# STM32H5F5xx register map
File version: 1.0
Registers are 32-bit, read-write, reset 0x0 unless marked. A register's access mark holds for its fields unless they carry their own. Offsets are from the block's base; [hi:lo] are bit positions; {n}, {i} and the like mark numbered series; 'fields as' and 'values as' point back to an identical list.

## RCC — Reset and Clock Control
Base 0x44020C00
Same registers: RCC_S 0x54020C00
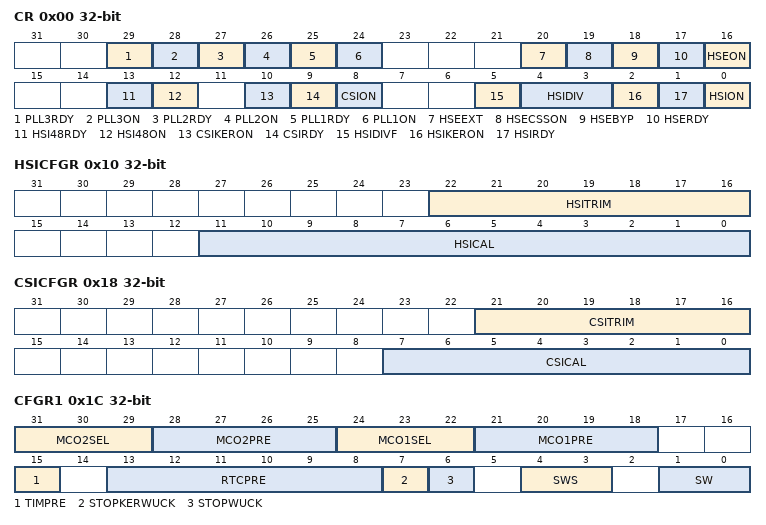
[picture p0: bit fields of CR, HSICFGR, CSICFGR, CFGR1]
0x00 CR — RCC clock control register
  [29] PLL3RDY — PLL3 ready
  [28] PLL3ON — PLL3 enable
  [27] PLL2RDY — PLL2 ready
  [26] PLL2ON — PLL2 enable
  [25] PLL1RDY — System PLL clock ready
  [24] PLL1ON — System PLL clock enable
  [20] HSEEXT — External High Speed clock type in Bypass mode
    0=ANALOG_TYPE (ANALOG clock used as HSE external clock source); 1=DIGITAL_TYPE (DIGITAL clock used as HSE external clock source)
  [19] HSECSSON — HSE Clock Security System enable
  [18] HSEBYP — External High Speed oscillator (HSE) clock bypass
  [17] HSERDY — External High Speed oscillator (HSE) clock ready
  [16] HSEON — External High Speed oscillator (HSE) clock enable
  [13] HSI48RDY — HSI48 clock ready
  [12] HSI48ON — HSI48 clock enable
  [10] CSIKERON — The Internal RC 4MHz oscillator (CSI) clock enable for some IPs Kernel
  [9] CSIRDY — The Internal RC 4MHz oscillator (CSI) clock ready
  [8] CSION — The Internal RC 4MHz oscillator (CSI) clock enable
  [5] HSIDIVF — HSI Divider flag
  [4:3] HSIDIV — Internal High Speed clock divider selection
    0=DIV_1 (HSI_DIV1 clock activation); 1=DIV_2 (HSI_DIV2 clock activation); 2=DIV_4 (HSI_DIV4 clock activation); 3=DIV_8 (HSI_DIV8 clock activation)
  [2] HSIKERON — Internal High Speed oscillator (HSI) clock enable for some IPs Kernel
  [1] HSIRDY — Internal High Speed oscillator (HSI) clock ready flag
  [0] HSION — Internal High Speed oscillator (HSI) clock enable
0x10 HSICFGR — RCC HSI Clock Calibration Register
  [22:16] HSITRIM — HSITRIM[6:0] bits
  [11:0] HSICAL — HSICAL[11:0] bits
0x14 CRRCR — RCC Clock Recovery RC Register
  [9:0] HSI48CAL — HSI48CAL[8:0] bits
0x18 CSICFGR — RCC CSI Clock Calibration Register
  [21:16] CSITRIM — CSITRIM[5:0] bits
  [7:0] CSICAL — CSICAL[7:0] bits
0x1C CFGR1 — RCC clock configuration register 1
  [31:29] MCO2SEL
  [28:25] MCO2PRE
  [24:22] MCO1SEL
  [21:18] MCO1PRE
  [15] TIMPRE
    0=TWICE; 1=FOUR_TIMES
  [13:8] RTCPRE — HSE division factor for RTC Clock
    0=NOCLOCK; {v}=DIV_{v} (v=2..63)
  [7] STOPKERWUCK — Kernel Clock Selection after a Wake Up from STOP
    0=HSI (HSI selection as kernel clock after wake-up from STOP); 1=CSI (CSI selection as kernel clock after wake-up from STOP)
  [6] STOPWUCK — Wake Up from stop and HSE CSS backup clock selection
    0=HSI (HSI selection as system clock after wake-up from STOP); 1=CSI (CSI selection as system clock after wake-up from STOP)
  [4:3] SWS — SWS[1:0] bits (System Clock Switch Status)
    0=HSI (HSI oscillator used as system clock); 1=CSI (CSI oscillator used as system clock); 2=HSE (HSE oscillator used as system clock); 3=PLL1 (PLL1 used as system clock)
  [1:0] SW — SW[1:0] bits (System clock Switch)
    0=HSI (HSI oscillator selection as system clock); 1=CSI (CSI oscillator selection as system clock); 2=HSE (HSE oscillator selection as system clock); 3=PLL1 (PLL1 selection as system clock)
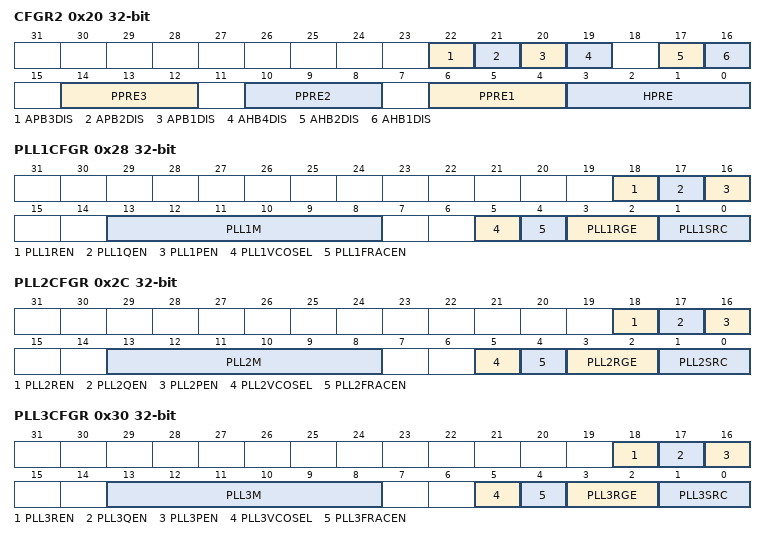
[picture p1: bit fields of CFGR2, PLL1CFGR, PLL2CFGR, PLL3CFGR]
0x20 CFGR2 — RCC clock configuration register 2
  [22] APB3DIS — APB3 clock disable
  [21] APB2DIS — APB2 clock disable
  [20] APB1DIS — APB1 clock disable
  [19] AHB4DIS — AHB4 clock disable
  [17] AHB2DIS — AHB2 clock disable
  [16] AHB1DIS — AHB1 clock disable
  [14:12] PPRE3 — PPRE3[2:0] bits (APB3 prescaler)
    0=DIV_1 (HCLK not divided); 4=DIV_2 (HCLK divided by 2); 5=DIV_4 (HCLK divided by 4); 6=DIV_8 (HCLK divided by 8); 7=DIV_16 (HCLK divided by 16)
  [10:8] PPRE2 — PPRE2[2:0] bits (APB2 prescaler)
    values as PPRE3
  [6:4] PPRE1 — PPRE1[2:0] bits (APB1 prescaler)
    values as PPRE3
  [3:0] HPRE — HPRE[3:0] bits (AHB prescaler)
    0=DIV_1 (SYSCLK not divided); 8=DIV_2 (SYSCLK divided by 2); 9=DIV_4 (SYSCLK divided by 4); 10=DIV_8 (SYSCLK divided by 8); 11=DIV_16 (SYSCLK divided by 16); 12=DIV_64 (SYSCLK divided by 64); 13=DIV_128 (SYSCLK divided by 128); 14=DIV_256 (SYSCLK divided by 256); 15=DIV_512 (SYSCLK divided by 512)
0x28 PLL1CFGR — RCC PLL1 Configuration Register
  [18] PLL1REN
  [17] PLL1QEN
  [16] PLL1PEN
  [13:8] PLL1M
  [5] PLL1VCOSEL
  [4] PLL1FRACEN
  [3:2] PLL1RGE
  [1:0] PLL1SRC
    0=NONE (No clock selected as main PLL1 entry clock source); 1=HSI (HSI clock selected as main PLL1 entry clock source); 2=CSI (CSI clock selected as main PLL1 entry clock source); 3=HSE (HSE clock selected as main PLL1 entry clock source)
0x2C PLL2CFGR — RCC PLL2 Configuration Register
  [18] PLL2REN
  [17] PLL2QEN
  [16] PLL2PEN
  [13:8] PLL2M
  [5] PLL2VCOSEL
  [4] PLL2FRACEN
  [3:2] PLL2RGE
  [1:0] PLL2SRC
    0=NONE (No clock selected as main PLL2 entry clock source); 2=CSI (CSI clock selected as main PLL2 entry clock source); 1=HSI (HSI clock selected as main PLL2 entry clock source); 3=HSE (HSE clock selected as main PLL2 entry clock source)
0x30 PLL3CFGR — RCC PLL3 Configuration Register
  [18] PLL3REN
  [17] PLL3QEN
  [16] PLL3PEN
  [13:8] PLL3M
  [5] PLL3VCOSEL
  [4] PLL3FRACEN
  [3:2] PLL3RGE
  [1:0] PLL3SRC
    0=NONE (No clock selected as main PLL3 entry clock source); 2=CSI (CSI clock selected as main PLL3 entry clock source); 1=HSI (HSI clock selected as main PLL3 entry clock source); 3=HSE (HSE clock selected as main PLL3 entry clock source)
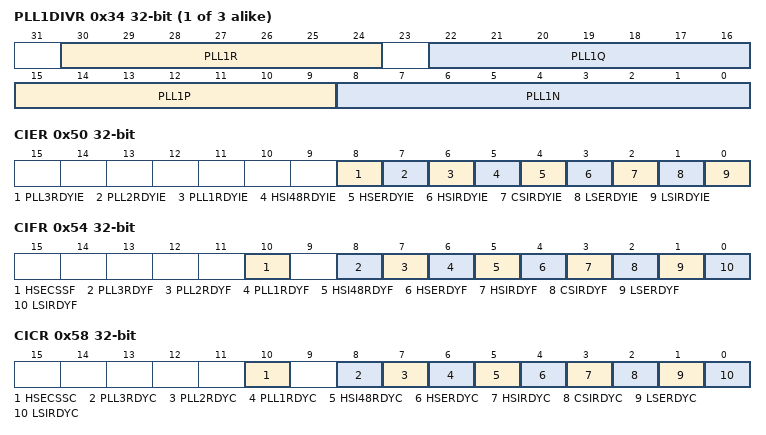
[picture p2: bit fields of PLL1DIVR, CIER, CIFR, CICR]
{0x2C+8i} PLL{i}DIVR (i=1..3) — RCC PLL{i} Dividers Configuration Register
  [30:24] PLL{i}R, [22:16] PLL{i}Q, [15:9] PLL{i}P, [8:0] PLL{i}N
{0x30+8i} PLL{i}FRACR (i=1..3) — RCC PLL{i} Fractional Divider Configuration Register
  [15:3] PLL{i}FRACN
0x50 CIER — RCC Clock Interrupt Enable Register
  [8] PLL3RDYIE, [7] PLL2RDYIE, [6] PLL1RDYIE, [5] HSI48RDYIE, [4] HSERDYIE, [3] HSIRDYIE, [2] CSIRDYIE, [1] LSERDYIE, [0] LSIRDYIE
0x54 CIFR — RCC Clock Interrupt Flag Register
  [10] HSECSSF, [8] PLL3RDYF, [7] PLL2RDYF, [6] PLL1RDYF, [5] HSI48RDYF, [4] HSERDYF, [3] HSIRDYF, [2] CSIRDYF, [1] LSERDYF, [0] LSIRDYF
0x58 CICR — RCC Clock Interrupt Clear Register
  [10] HSECSSC, [8] PLL3RDYC, [7] PLL2RDYC, [6] PLL1RDYC, [5] HSI48RDYC, [4] HSERDYC, [3] HSIRDYC, [2] CSIRDYC, [1] LSERDYC, [0] LSIRDYC
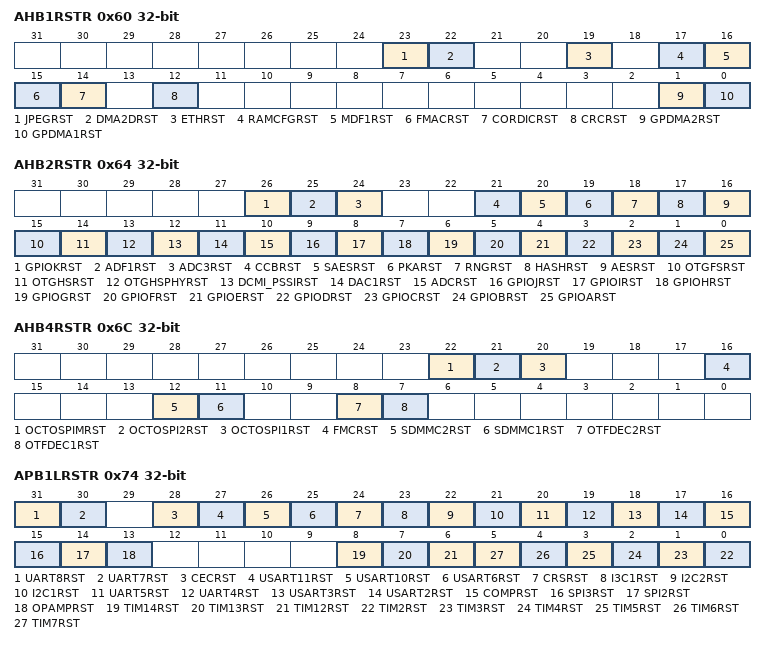
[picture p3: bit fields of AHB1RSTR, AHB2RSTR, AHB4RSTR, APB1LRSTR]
0x60 AHB1RSTR — RCC AHB1 Peripherals Reset Register
  [23] JPEGRST, [22] DMA2DRST, [19] ETHRST, [17] RAMCFGRST, [16] MDF1RST, [15] FMACRST, [14] CORDICRST, [12] CRCRST, [1] GPDMA2RST, [0] GPDMA1RST
0x64 AHB2RSTR — RCC AHB2 Peripherals Reset Register
  [26] GPIOKRST, [25] ADF1RST, [24] ADC3RST, [21] CCBRST, [20] SAESRST, [19] PKARST, [18] RNGRST, [17] HASHRST, [16] AESRST, [15] OTGFSRST, [14] OTGHSRST, [13] OTGHSPHYRST, [12] DCMI_PSSIRST, [11] DAC1RST, [10] ADCRST, [9] GPIOJRST, [8] GPIOIRST, [7] GPIOHRST, [6] GPIOGRST, [5] GPIOFRST, [4] GPIOERST, [3] GPIODRST, [2] GPIOCRST, [1] GPIOBRST, [0] GPIOARST
0x6C AHB4RSTR — RCC AHB4 Peripherals Reset Register
  [22] OCTOSPIMRST, [21] OCTOSPI2RST, [20] OCTOSPI1RST, [16] FMCRST, [12] SDMMC2RST, [11] SDMMC1RST, [8] OTFDEC2RST, [7] OTFDEC1RST
0x74 APB1LRSTR — RCC APB1 Peripherals reset Low Word register
  [31] UART8RST, [30] UART7RST, [28] CECRST, [27] USART11RST, [26] USART10RST, [25] USART6RST, [24] CRSRST, [23] I3C1RST, [22] I2C2RST, [21] I2C1RST, [20] UART5RST, [19] UART4RST, [18] USART3RST, [17] USART2RST, [16] COMPRST, [15] SPI3RST, [14] SPI2RST, [13] OPAMPRST, [8] TIM14RST, [7] TIM13RST, [6] TIM12RST, [n-2] TIM{n}RST (n=2..7)
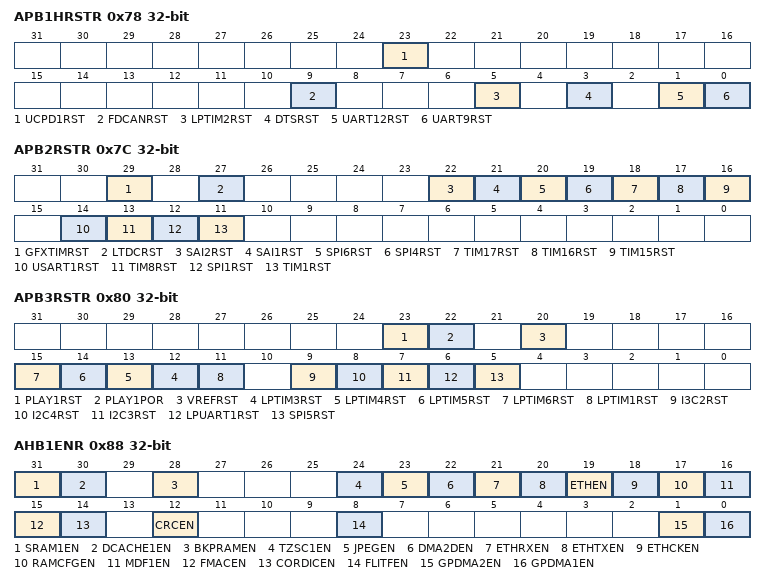
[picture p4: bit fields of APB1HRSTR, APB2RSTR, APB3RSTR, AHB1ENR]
0x78 APB1HRSTR — RCC APB1 Peripherals reset High Word register
  [23] UCPD1RST, [9] FDCANRST, [5] LPTIM2RST, [3] DTSRST, [1] UART12RST, [0] UART9RST
0x7C APB2RSTR — RCC APB2 Peripherals Reset Register
  [29] GFXTIMRST, [27] LTDCRST, [22] SAI2RST, [21] SAI1RST, [20] SPI6RST, [19] SPI4RST, [18] TIM17RST, [17] TIM16RST, [16] TIM15RST, [14] USART1RST, [13] TIM8RST, [12] SPI1RST, [11] TIM1RST
0x80 APB3RSTR — RCC APB3 Peripherals Reset Register
  [23] PLAY1RST, [22] PLAY1POR, [20] VREFRST, [n+9] LPTIM{n}RST (n=3..6), [11] LPTIM1RST, [9] I3C2RST, [8] I2C4RST, [7] I2C3RST, [6] LPUART1RST, [5] SPI5RST
0x88 AHB1ENR — RCC AHB1 Peripherals Clock Enable Register
  [31] SRAM1EN, [30] DCACHE1EN, [28] BKPRAMEN, [24] TZSC1EN, [23] JPEGEN, [22] DMA2DEN, [21] ETHRXEN, [20] ETHTXEN, [19] ETHEN, [18] ETHCKEN, [17] RAMCFGEN, [16] MDF1EN, [15] FMACEN, [14] CORDICEN, [12] CRCEN, [8] FLITFEN, [1] GPDMA2EN, [0] GPDMA1EN
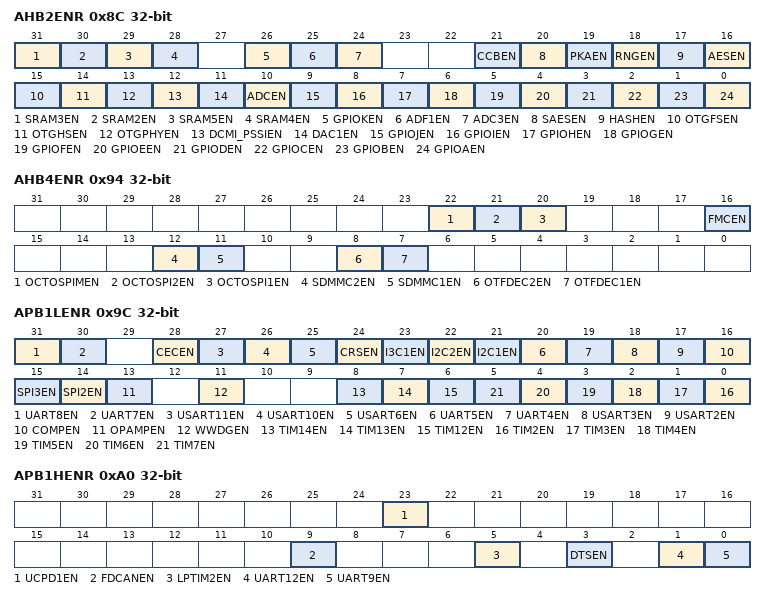
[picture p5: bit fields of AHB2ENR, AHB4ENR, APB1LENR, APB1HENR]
0x8C AHB2ENR — RCC AHB2 Peripherals Clock Enable Register
  [31] SRAM3EN, [30] SRAM2EN, [29] SRAM5EN, [28] SRAM4EN, [26] GPIOKEN, [25] ADF1EN, [24] ADC3EN, [21] CCBEN, [20] SAESEN, [19] PKAEN, [18] RNGEN, [17] HASHEN, [16] AESEN, [15] OTGFSEN, [14] OTGHSEN, [13] OTGPHYEN, [12] DCMI_PSSIEN, [11] DAC1EN, [10] ADCEN, [9] GPIOJEN, [8] GPIOIEN, [7] GPIOHEN, [6] GPIOGEN, [5] GPIOFEN, [4] GPIOEEN, [3] GPIODEN, [2] GPIOCEN, [1] GPIOBEN, [0] GPIOAEN
0x94 AHB4ENR — RCC AHB4 Peripherals Clock Enable Register
  [22] OCTOSPIMEN, [21] OCTOSPI2EN, [20] OCTOSPI1EN, [16] FMCEN, [12] SDMMC2EN, [11] SDMMC1EN, [8] OTFDEC2EN, [7] OTFDEC1EN
0x9C APB1LENR — RCC APB1 Peripherals clock Enable Low Word register
  [31] UART8EN, [30] UART7EN, [28] CECEN, [27] USART11EN, [26] USART10EN, [25] USART6EN, [24] CRSEN, [23] I3C1EN, [22] I2C2EN, [21] I2C1EN, [20] UART5EN, [19] UART4EN, [18] USART3EN, [17] USART2EN, [16] COMPEN, [15] SPI3EN, [14] SPI2EN, [13] OPAMPEN, [11] WWDGEN, [8] TIM14EN, [7] TIM13EN, [6] TIM12EN, [n-2] TIM{n}EN (n=2..7)
0xA0 APB1HENR — RCC APB1 Peripherals clock Enable High Word register
  [23] UCPD1EN, [9] FDCANEN, [5] LPTIM2EN, [3] DTSEN, [1] UART12EN, [0] UART9EN
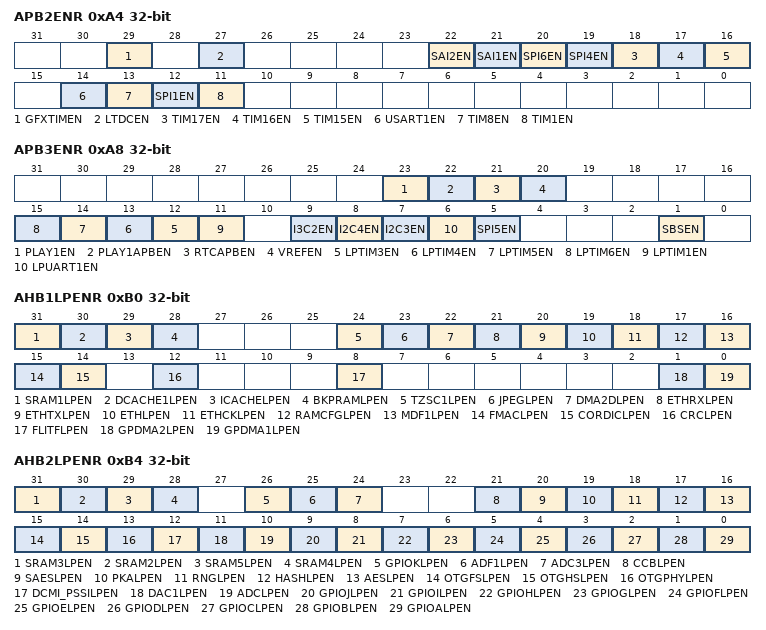
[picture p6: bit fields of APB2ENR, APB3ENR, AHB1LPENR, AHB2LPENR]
0xA4 APB2ENR — RCC APB2 Peripherals Clock Enable Register
  [29] GFXTIMEN, [27] LTDCEN, [22] SAI2EN, [21] SAI1EN, [20] SPI6EN, [19] SPI4EN, [18] TIM17EN, [17] TIM16EN, [16] TIM15EN, [14] USART1EN, [13] TIM8EN, [12] SPI1EN, [11] TIM1EN
0xA8 APB3ENR — RCC APB3 Peripherals Clock Enable Register
  [23] PLAY1EN, [22] PLAY1APBEN, [21] RTCAPBEN, [20] VREFEN, [n+9] LPTIM{n}EN (n=3..6), [11] LPTIM1EN, [9] I3C2EN, [8] I2C4EN, [7] I2C3EN, [6] LPUART1EN, [5] SPI5EN, [1] SBSEN
0xB0 AHB1LPENR — RCC AHB1 Peripheral sleep clock Register
  [31] SRAM1LPEN, [30] DCACHE1LPEN, [29] ICACHELPEN, [28] BKPRAMLPEN, [24] TZSC1LPEN, [23] JPEGLPEN, [22] DMA2DLPEN, [21] ETHRXLPEN, [20] ETHTXLPEN, [19] ETHLPEN, [18] ETHCKLPEN, [17] RAMCFGLPEN, [16] MDF1LPEN, [15] FMACLPEN, [14] CORDICLPEN, [12] CRCLPEN, [8] FLITFLPEN, [1] GPDMA2LPEN, [0] GPDMA1LPEN
0xB4 AHB2LPENR — RCC AHB2 Peripheral sleep clock Register
  [31] SRAM3LPEN, [30] SRAM2LPEN, [29] SRAM5LPEN, [28] SRAM4LPEN, [26] GPIOKLPEN, [25] ADF1LPEN, [24] ADC3LPEN, [21] CCBLPEN, [20] SAESLPEN, [19] PKALPEN, [18] RNGLPEN, [17] HASHLPEN, [16] AESLPEN, [15] OTGFSLPEN, [14] OTGHSLPEN, [13] OTGPHYLPEN, [12] DCMI_PSSILPEN, [11] DAC1LPEN, [10] ADCLPEN, [9] GPIOJLPEN, [8] GPIOILPEN, [7] GPIOHLPEN, [6] GPIOGLPEN, [5] GPIOFLPEN, [4] GPIOELPEN, [3] GPIODLPEN, [2] GPIOCLPEN, [1] GPIOBLPEN, [0] GPIOALPEN
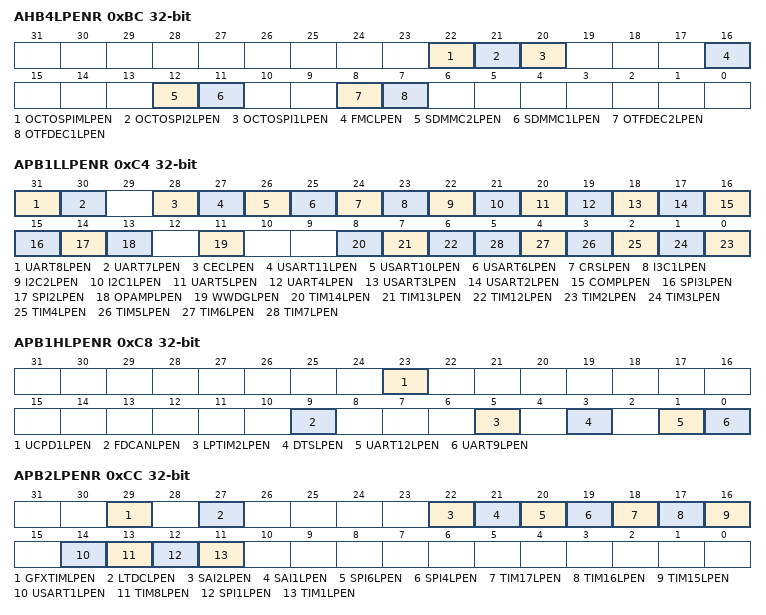
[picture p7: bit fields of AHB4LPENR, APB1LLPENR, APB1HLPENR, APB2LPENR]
0xBC AHB4LPENR — RCC AHB4 Peripherals sleep clock Register
  [22] OCTOSPIMLPEN, [21] OCTOSPI2LPEN, [20] OCTOSPI1LPEN, [16] FMCLPEN, [12] SDMMC2LPEN, [11] SDMMC1LPEN, [8] OTFDEC2LPEN, [7] OTFDEC1LPEN
0xC4 APB1LLPENR — RCC APB1 Peripherals sleep clock Low Word Register
  [31] UART8LPEN, [30] UART7LPEN, [28] CECLPEN, [27] USART11LPEN, [26] USART10LPEN, [25] USART6LPEN, [24] CRSLPEN, [23] I3C1LPEN, [22] I2C2LPEN, [21] I2C1LPEN, [20] UART5LPEN, [19] UART4LPEN, [18] USART3LPEN, [17] USART2LPEN, [16] COMPLPEN, [15] SPI3LPEN, [14] SPI2LPEN, [13] OPAMPLPEN, [11] WWDGLPEN, [8] TIM14LPEN, [7] TIM13LPEN, [6] TIM12LPEN, [n-2] TIM{n}LPEN (n=2..7)
0xC8 APB1HLPENR — RCC APB1 Peripherals sleep clock High Word Register
  [23] UCPD1LPEN, [9] FDCANLPEN, [5] LPTIM2LPEN, [3] DTSLPEN, [1] UART12LPEN, [0] UART9LPEN
0xCC APB2LPENR — RCC APB2 Peripherals sleep clock Register
  [29] GFXTIMLPEN, [27] LTDCLPEN, [22] SAI2LPEN, [21] SAI1LPEN, [20] SPI6LPEN, [19] SPI4LPEN, [18] TIM17LPEN, [17] TIM16LPEN, [16] TIM15LPEN, [14] USART1LPEN, [13] TIM8LPEN, [12] SPI1LPEN, [11] TIM1LPEN
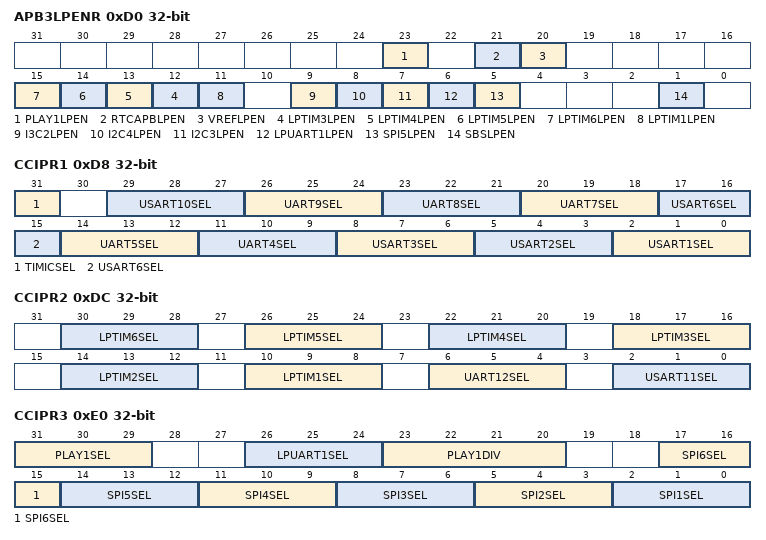
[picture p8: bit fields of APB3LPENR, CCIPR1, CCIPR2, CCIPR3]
0xD0 APB3LPENR — RCC APB3 Peripherals Clock Low Power Enable Register
  [23] PLAY1LPEN, [21] RTCAPBLPEN, [20] VREFLPEN, [n+9] LPTIM{n}LPEN (n=3..6), [11] LPTIM1LPEN, [9] I3C2LPEN, [8] I2C4LPEN, [7] I2C3LPEN, [6] LPUART1LPEN, [5] SPI5LPEN, [1] SBSLPEN
0xD8 CCIPR1 — RCC IPs Clocks Configuration Register 1
  [31] TIMICSEL, [29:27] USART10SEL, [26:24] UART9SEL, [23:21] UART8SEL, [20:18] UART7SEL, [17:15] USART6SEL, [14:12] UART5SEL, [11:9] UART4SEL, [8:6] USART3SEL, [5:3] USART2SEL, [2:0] USART1SEL
0xDC CCIPR2 — RCC IPs Clocks Configuration Register 2
  [4n+6:4n+4] LPTIM{n}SEL (n=1..6), [6:4] UART12SEL, [2:0] USART11SEL
0xE0 CCIPR3 — RCC IPs Clocks Configuration Register 3
  [31:29] PLAY1SEL
    0=PCLK3; 1=PLL2P; 2=PLL3R; 3=LSE; 4=LSI; 5=CLKP
  [26:24] LPUART1SEL
    0=PCLK3 (PCLK3 clock used as LPUART1 clock source); 1=PLL2Q (PLL2Q clock used as LPUART1 clock source); 2=PLL3Q (PLL3Q clock used as LPUART1 clock source); 3=HSI (HSI clock used as LPUART1 clock source); 4=CSI (CSI clock used as LPUART1 clock source); 5=LSE (LSE clock used as LPUART1 clock source)
  [23:20] PLAY1DIV
    0=DIV_1 (PLAY1 not divided (default)); 1=DIV_2 (PLAY1 divided by 2); 2=DIV_4 (PLAY1 divided by 4); 3=DIV_8 (PLAY1 divided by 8); 4=DIV_16 (PLAY1 divided by 16); 5=DIV_32 (PLAY1 divided by 32); 6=DIV_64 (PLAY1 divided by 64); 7=DIV_128 (PLAY1 divided by 128); 8=DIV_256 (PLAY1 divided by 256); 9=DIV_512 (PLAY1 divided by 512); 10=DIV_1024 (PLAY1 divided by 1024); 11=DIV_2048 (PLAY1 divided by 2048); 12=DIV_4096 (PLAY1 divided by 4096); 13=DIV_8192 (PLAY1 divided by 8192); 14=DIV_16384 (PLAY1 divided by 16384); 15=DIV_32768
  [3n-1:3n-3] SPI{n}SEL (n=1..6)
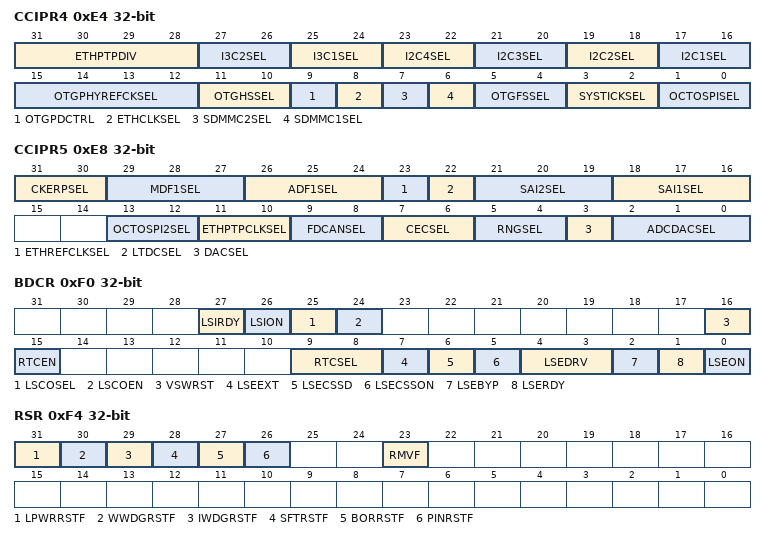
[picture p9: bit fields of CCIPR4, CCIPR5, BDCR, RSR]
0xE4 CCIPR4 — RCC IPs Clocks Configuration Register 4
  [31:28] ETHPTPDIV
    0=DIV_1 (ETHPTP not divided (default)); {v}=DIV_{v+1} (ETHPTP divided by {v+1}) (v=1..14); 15=DIV_16
  [27:26] I3C2SEL
  [25:24] I3C1SEL
  [2n+15:2n+14] I2C{n}SEL (n=1..4)
  [15:12] OTGPHYREFCKSEL
    3=OTGPHYREFCKCLKSOURCE_16M; 8=OTGPHYREFCKCLKSOURCE_19_2M; 9=OTGPHYREFCKCLKSOURCE_20M; 10=OTGPHYREFCKCLKSOURCE_24M; 14=OTGPHYREFCKCLKSOURCE_26M; 11=OTGPHYREFCKCLKSOURCE_32M
  [11:10] OTGHSSEL
    0=HSE; 1=PLL3Q; 2=HSE_DIV2; 3=PLL1Q_DIV2
  [9] OTGPDCTRL
  [8] ETHCLKSEL
    0=HSE; 1=PLL1Q
  [7] SDMMC2SEL
  [6] SDMMC1SEL
  [5:4] OTGFSSEL
    0=HSI48; 1=PLL1Q; 2=PLL3Q; 3=CLK48
  [3:2] SYSTICKSEL
    1=LSI (LSI clock used as SYSTICK clock source); 2=LSE (LSE clock used as SYSTICK clock source); 0=HCLKDIV8 (HCLKDIV8 clock used as SYSTICK clock source)
  [1:0] OCTOSPISEL
    0=HCLK (AHB clock used as OctoSPI kernel clock source); 1=PLL1Q (PLL1 Q clock used as OctoSPI kernel clock source); 2=PLL2R (PLL2 R clock used as OctoSPI kernel clock source); 3=CLKP (CLKP clock used as OctoSPI clock source)
0xE8 CCIPR5 — RCC IPs Clocks Configuration Register 5
  [31:30] CKERPSEL
    0=HSI (HSI clock used as CLKP clock source); 1=CSI (CSI clock used as CLKP clock source); 2=HSE (HSE clock used as CLKP clock source); 3=NONE (No clock selected as CLKP clock source)
  [29:27] MDF1SEL
    0=PLL1Q; 1=PLL2P; 2=PLL3P; 3=PIN; 4=CLKP
  [26:24] ADF1SEL
    0=PLL1Q; 1=PLL2P; 2=PLL3P; 3=PIN; 4=CLKP
  [23] ETHREFCLKSEL
    0=PLL1Q; 1=PLL1R
  [22] LTDCSEL
    0=PLL3R; 1=PLL2R
  [21:19] SAI2SEL
  [18:16] SAI1SEL
  [13:12] OCTOSPI2SEL
    0=HCLK (AHB clock used as OctoSPI2 kernel clock source); 1=PLL1Q (PLL1 Q clock used as OctoSPI2 kernel clock source); 2=PLL2R (PLL2 R clock used as OctoSPI2 kernel clock source); 3=CLKP (CLKP clock used as OctoSPI2 clock source)
  [11:10] ETHPTPCLKSEL
    0=HCLK; 1=PLL1R; 2=PLL1Q; 3=PLL3P
  [9:8] FDCANSEL
    0=HSE (HSE clock used as FDCAN kernel clock source); 1=PLL1Q (PLL1 Q clock used as FDCAN kernel clock source); 2=PLL2Q (PLL2 Q clock used as FDCAN kernel clock source)
  [7:6] CECSEL
    0=LSE (LSE clock used as CEC clock); 1=LSI (LSI clock used as CEC clock); 2=CSI_DIV122 (CSI clock divied by 122 used as CEC clock)
  [5:4] RNGSEL
    0=HSI48 (HSI48 clock used as RNG clock source); 1=PLL1Q (PLL1 Q clock used as RNG clock source); 2=LSE (LSE clock used as RNG clock source); 3=LSI (LSI clock used as RNG clock source)
  [3] DACSEL
    0=LSE (LSE clock used as DAC low-power clock); 1=LSI (LSI clock used as DAC low-power clock)
  [2:0] ADCDACSEL
    0=HCLK (AHB clock used as ADCDAC clock source); 1=SYSCLK (SYSCLK clock used as ADCDAC clock source); 2=PLL2R (PLL2 R clock used as ADCDAC clock source); 3=HSE (HSE clock used as ADCDAC clock source); 4=HSI (HSI clock used as ADCDAC clock source); 5=CSI (CSI clock used as ADCDAC clock source)
0xF0 BDCR — RCC VSW Backup Domain & V33 Domain Control Register
  [27] LSIRDY
  [26] LSION
  [25] LSCOSEL
    0=LSI (LSI selection for low speed clock); 1=LSE (LSE selection for low speed clock)
  [24] LSCOEN
  [16] VSWRST
  [15] RTCEN
  [9:8] RTCSEL
    0=NONE (No clock used as RTC clock); 1=LSE (LSE oscillator clock used as RTC clock); 2=LSI (LSI oscillator clock used as RTC clock); 3=HSE_DIV (HSE oscillator clock divided by RTCPRE used as RTC clock)
  [7] LSEEXT
    0=ANALOG_TYPE (ANALOG clock used as LSE external clock source); 1=DIGITAL_TYPE (DIGITAL clock used as LSE external clock source)
  [6] LSECSSD
  [5] LSECSSON
  [4:3] LSEDRV
    0=LOW (Xtal mode lower driving capability); 1=MEDIUMLOW (Xtal mode medium low driving capability); 2=MEDIUMHIGH (Xtal mode medium high driving capability); 3=HIGH (Xtal mode higher driving capability)
  [2] LSEBYP
  [1] LSERDY
  [0] LSEON
0xF4 RSR — RCC Reset status Register
  [31] LPWRRSTF, [30] WWDGRSTF, [29] IWDGRSTF, [28] SFTRSTF, [27] BORRSTF, [26] PINRSTF, [23] RMVF
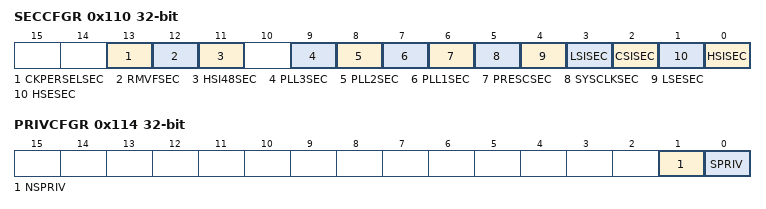
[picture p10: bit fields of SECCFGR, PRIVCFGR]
0x110 SECCFGR — RCC Secure mode configuration register
  [13] CKPERSELSEC, [12] RMVFSEC, [11] HSI48SEC, [9] PLL3SEC, [8] PLL2SEC, [7] PLL1SEC, [6] PRESCSEC, [5] SYSCLKSEC, [4] LSESEC, [3] LSISEC, [2] CSISEC, [1] HSESEC, [0] HSISEC
0x114 PRIVCFGR — RCC Privilege configuration register
  [1] NSPRIV, [0] SPRIV
